# LPC5411x register map
Vendor: nxp.com; File version: 1.2
CPU: CM4 r0p1, little endian, MPU, FPU, VTOR, vendor SysTick, 3 interrupt priority bits
Registers are 32-bit, read-write, reset 0x0 unless marked. A register's access mark holds for its fields unless they carry their own. Offsets are from the block's base; [hi:lo] are bit positions; {n}, {i} and the like mark numbered series; 'fields as' and 'values as' point back to an identical list.

## UTICK — LPC5411x Micro-tick Timer (UTICK)
Base 0x4000E000
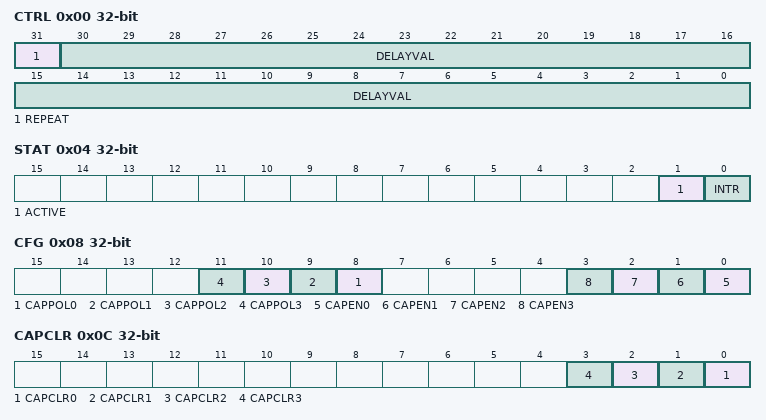
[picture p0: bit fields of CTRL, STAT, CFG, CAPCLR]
0x00 CTRL — Control register.
  [31] REPEAT — Repeat delay. 0 = One-time delay. 1 = Delay repeats continuously.
  [30:0] DELAYVAL — Tick interval value. The delay will be equal to DELAYVAL + 1 periods of the timer clock. The minimum usable value is 1, for a delay of 2 timer clocks. A value of 0 stops the timer.
0x04 STAT — Status register.
  [1] ACTIVE — Active flag. 0 = The Micro-Tick Timer is stopped. 1 = The Micro-Tick Timer is currently active.
  [0] INTR — Interrupt flag. 0 = No interrupt is pending. 1 = An interrupt is pending. A write of any value to this register clears this flag.
0x08 CFG — Capture configuration register.
  [n+8] CAPPOL{n} (n=0..3) — Capture Polarity {n}. 0 = Positive edge capture, 1 = Negative edge capture.
  [n] CAPEN{n} (n=0..3) — Enable Capture {n}. 1 = Enabled, 0 = Disabled.
0x0C CAPCLR reset not defined — Capture clear register.
  [n] CAPCLR{n} wo (n=0..3) — Clear capture {n}. Writing 1 to this bit clears the CAP{n} register value.
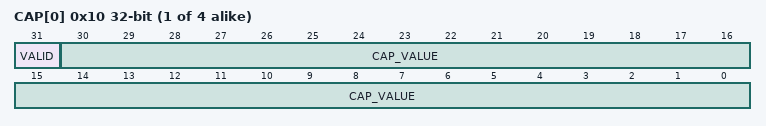
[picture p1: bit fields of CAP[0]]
{0x10+4i} CAP[{i}] (i=0..3) — Capture register .
  [31] VALID ro — Capture Valid. When 1, a value has been captured based on a transition of the related UTICK_CAPn pin. Cleared by writing to the related bit in the CAPCLR register.
  [30:0] CAP_VALUE ro — Capture value for the related capture event (UTICK_CAPn. Note: the value is 1 lower than the actual value of the Micro-tick Timer at the moment of the capture event.

## FLEXCOMM0 — LPC5411x Flexcomm serial communication
Base 0x40086000
Same registers: FLEXCOMM1 0x40087000, FLEXCOMM2 0x40088000, FLEXCOMM3 0x40089000, FLEXCOMM4 0x4008A000, FLEXCOMM5 0x40096000, FLEXCOMM6 0x40097000, FLEXCOMM7 0x40098000
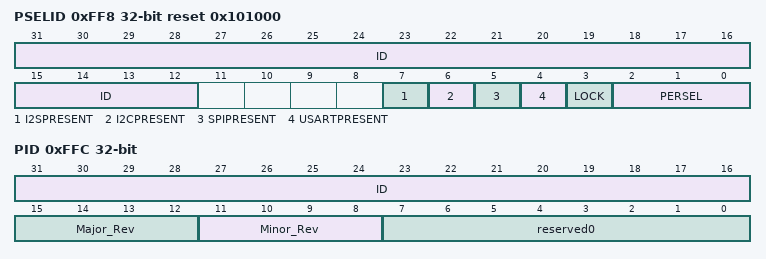
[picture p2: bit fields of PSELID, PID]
0xFF8 PSELID reset 0x101000 — Peripheral Select and Flexcomm ID register.
  [31:12] ID ro — Flexcomm ID.
  [7] I2SPRESENT ro — I 2S present indicator. This field is Read-only.
    on read: 0=NOT_PRESENT (This Flexcomm does not include the I2S function.); 1=PRESENT (This Flexcomm includes the I2S function.)
  [6] I2CPRESENT ro — I2C present indicator. This field is Read-only.
    on read: 0=NOT_PRESENT (This Flexcomm does not include the I2C function.); 1=PRESENT (This Flexcomm includes the I2C function.)
  [5] SPIPRESENT ro — SPI present indicator. This field is Read-only.
    on read: 0=NOT_PRESENT (This Flexcomm does not include the SPI function.); 1=PRESENT (This Flexcomm includes the SPI function.)
  [4] USARTPRESENT ro — USART present indicator. This field is Read-only.
    on read: 0=NOT_PRESENT (This Flexcomm does not include the USART function.); 1=PRESENT (This Flexcomm includes the USART function.)
  [3] LOCK — Lock the peripheral select. This field is writable by software.
    0=UNLOCKED (Peripheral select can be changed by software.); 1=LOCKED (Peripheral select is locked and cannot be changed until this Flexcomm or the entire device is reset.)
  [2:0] PERSEL — Peripheral Select. This field is writable by software.
    0=NO_PERIPH_SELECTED (No peripheral selected.); 1=USART (USART function selected.); 2=SPI (SPI function selected.); 3=I2C (I2C function selected.); 4=I2S_TRANSMIT (I2S transmit function selected.); 5=I2S_RECEIVE (I2S receive function selected.)
0xFFC PID (reset mask 0xFFFFFF00) — Peripheral identification register.
  [31:16] ID ro — Module identifier for the selected function.
  [15:12] Major_Rev ro — Major revision of module implementation.
  [11:8] Minor_Rev ro — Minor revision of module implementation.
  [7:0] reserved0 ro

## MAILBOX — LPC5411x Mailbox
Base 0x4008B000
0x00 IRQ0 — Interrupt request register for the Cortex-M0+ CPU.
  [31:0] INTREQ — If any bit is set, an interrupt request is sent to the Cortex-M0+ interrupt controller.
0x04 IRQ0SET reset not defined — Set bits in IRQ0
  [31:0] INTREQSET wo — Writing 1 sets the corresponding bit in the IRQ0 register.
0x08 IRQ0CLR reset not defined — Clear bits in IRQ0
  [31:0] INTREQCLR wo — Writing 1 clears the corresponding bit in the IRQ0 register.
0x10 IRQ1 — Interrupt request register for the Cortex M4 CPU.
  fields as IRQ0
0x14 IRQ1SET reset not defined — Set bits in IRQ1
  [31:0] INTREQSET wo — Writing 1 sets the corresponding bit in the IRQ1 register.
0x18 IRQ1CLR reset not defined — Clear bits in IRQ1
  [31:0] INTREQCLR wo — Writing 1 clears the corresponding bit in the IRQ1 register.
0xF8 MUTEX reset 0x1 — Mutual exclusion register[1]
  [0] EX — Cleared when read, set when written. See usage description above.

## CRC_ENGINE — LPC5411x CRC engine
Base 0x40095000
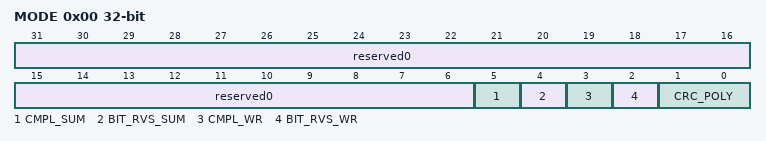
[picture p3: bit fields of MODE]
0x00 MODE (reset mask 0x3F) — CRC mode register
  [31:6] reserved0 wo — Always 0 when read
  [5] CMPL_SUM — CRC sum complement: 1 = 1's complement for CRC_SUM 0 = No 1's complement for CRC_SUM
  [4] BIT_RVS_SUM — CRC sum bit order: 1 = Bit order reverse for CRC_SUM 0 = No bit order reverse for CRC_SUM
  [3] CMPL_WR — Data complement: 1 = 1's complement for CRC_WR_DATA 0 = No 1's complement for CRC_WR_DATA
  [2] BIT_RVS_WR — Data bit order: 1 = Bit order reverse for CRC_WR_DATA (per byte) 0 = No bit order reverse for CRC_WR_DATA (per byte)
  [1:0] CRC_POLY — CRC polynomial: 1X = CRC-32 polynomial 01 = CRC-16 polynomial 00 = CRC-CCITT polynomial
0x04 SEED reset 0xFFFF — CRC seed register
  [31:0] CRC_SEED — A write access to this register will load CRC seed value to CRC_SUM register with selected bit order and 1's complement pre-processes. A write access to this register will overrule the CRC calculation in progresses.
0x08 SUM reset 0xFFFF — CRC checksum register
  [31:0] CRC_SUM ro — The most recent CRC sum can be read through this register with selected bit order and 1's complement post-processes.
0x08 WR_DATA reset not defined — CRC data register
  [31:0] CRC_WR_DATA wo — Data written to this register will be taken to perform CRC calculation with selected bit order and 1's complement pre-process. Any write size 8, 16 or 32-bit are allowed and accept back-to-back transactions.
